# MB9AF15xN register map
File version: 1.7
Registers are 32-bit, read-write, reset 0x0 unless marked. A register's access mark holds for its fields unless they carry their own. Offsets are from the block's base; [hi:lo] are bit positions; {n}, {i} and the like mark numbered series; 'fields as' and 'values as' point back to an identical list.

## WC — Watch Counter
Base 0x4003A000
0x00 WCRD 8-bit ro — Watch Counter Read Register
  [5:0] CTR — counter value
0x01 WCRL 8-bit — Watch Counter Reload Register
  [5:0] RLC — reload value
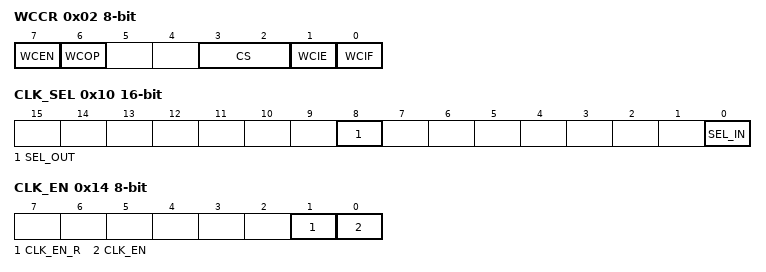
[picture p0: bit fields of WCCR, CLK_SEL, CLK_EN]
0x02 WCCR 8-bit — Watch Counter Control Register
  [7] WCEN — Watch counter operation enable bit
  [6] WCOP ro — Watch counter operating state flag
  [3:2] CS — Count clock select bits
  [1] WCIE — Interrupt request enable bit
  [0] WCIF — Interrupt request flag bit
0x10 CLK_SEL 16-bit — Clock Selection Register
  [8] SEL_OUT — Output clock selection bit
  [0] SEL_IN — Input clock selection bit
0x14 CLK_EN 8-bit — Division Clock Enable Register
  [1] CLK_EN_R — Division clock enable read bit
  [0] CLK_EN — Division clock enable bit

## MFT_PPG — PPG Configuration
Base 0x40024000
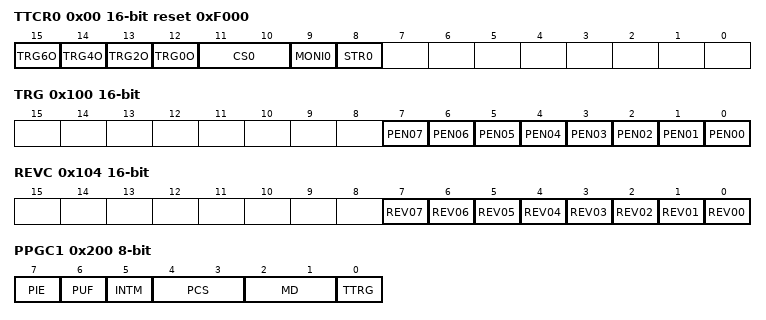
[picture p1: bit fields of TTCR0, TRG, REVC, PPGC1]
0x00 TTCR0 16-bit reset 0xF000 — PPG Start Trigger Control Register 0
  [15] TRG6O — PPG6 trigger stop bit
  [14] TRG4O — PPG4 trigger stop bit
  [13] TRG2O — PPG2 trigger stop bit
  [12] TRG0O — PPG0 trigger stop bit
  [11:10] CS0 — 8-bit UP counter clock select bits for comparison
  [9] MONI0 ro — 8-bit UP counter operation state monitor bit for comparison
  [8] STR0 — 8-bit UP counter operation enable bit for comparison
0x08 COMP0 16-bit (reset mask 0xFF00) — PPG Compare Register 0
0x0C COMP2 8-bit — PPG Compare Register 2
0x10 COMP4 16-bit (reset mask 0xFF00) — PPG Compare Register 4
0x14 COMP6 8-bit — PPG Compare Register 6
0x100 TRG 16-bit — PPG Start Register 0
  [n] PEN{n:02} (n=0..7) — PPG{n} Start Trigger bit
0x104 REVC 16-bit — Output Reverse Register 0
  [n] REV{n:02} (n=0..7) — PPG{n} Output Reverse Enable bit
0x200 PPGC1 8-bit — PPG Operation Mode Control Register 1
  [7] PIE — PPG Interrupt Enable bit
  [6] PUF — PPG Counter Underflow bit
  [5] INTM — Interrupt Mode Select bit
  [4:3] PCS — PPG DOWN Counter Operation Clock Select bits
  [2:1] MD — PPG Operation Mode Set bits
  [0] TTRG — PPG start trigger select bit
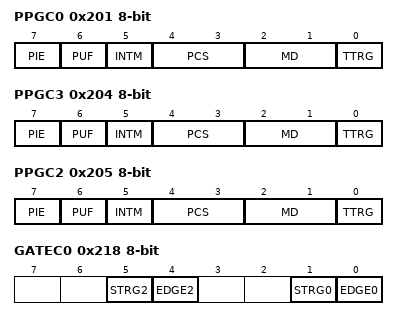
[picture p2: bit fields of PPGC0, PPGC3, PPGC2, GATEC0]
0x201 PPGC0 8-bit — PPG Operation Mode Control Register 0
  fields as PPGC1
0x204 PPGC3 8-bit — PPG Operation Mode Control Register 3
  fields as PPGC1
0x205 PPGC2 8-bit — PPG Operation Mode Control Register 2
  fields as PPGC1
{0x208+4i} PRLL{i} 8-bit reset not defined (i=0..3) — PPG{i} Reload Registers Low
  [7:0] PRLL — Reload Registers Low
{0x209+4i} PRLH{i} 8-bit reset not defined (i=0..3) — PPG{i} Reload Registers High
  [7:0] PRLH — Reload Registers High
0x218 GATEC0 8-bit — PPG Gate Function Control Registers 0
  [5] STRG2 — Select a trigger for PPG2
  [4] EDGE2 — Select Start Effective Level for PPG2
  [1] STRG0 — Select a trigger for PPG0
  [0] EDGE0 — Select Start Effective Level for PPG0
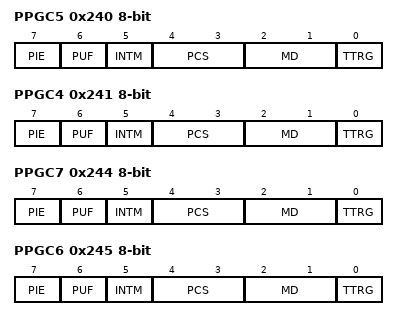
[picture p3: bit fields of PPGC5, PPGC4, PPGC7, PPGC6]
0x240 PPGC5 8-bit — PPG Operation Mode Control Register 5
  fields as PPGC1
0x241 PPGC4 8-bit — PPG Operation Mode Control Register 4
  fields as PPGC1
0x244 PPGC7 8-bit — PPG Operation Mode Control Register 7
  fields as PPGC1
0x245 PPGC6 8-bit — PPG Operation Mode Control Register 6
  fields as PPGC1
{0x238+4i} PRLL{i} 8-bit reset not defined (i=4..7) — PPG{i} Reload Registers Low
  [7:0] PRLL — Reload Registers Low
{0x239+4i} PRLH{i} 8-bit reset not defined (i=4..7) — PPG{i} Reload Registers High
  [7:0] PRLH — Reload Registers High
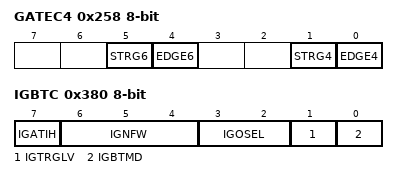
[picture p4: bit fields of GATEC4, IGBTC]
0x258 GATEC4 8-bit — PPG Gate Function Control Registers 4
  [5] STRG6 — Select a trigger for PPG6
  [4] EDGE6 — Select Start Effective Level for PPG6
  [1] STRG4 — Select a trigger for PPG4
  [0] EDGE4 — Select Start Effective Level for PPG4
0x380 IGBTC 8-bit — IGBT Mode Control Register
  [7] IGATIH — Stop prohibition mode selection in output active bit
  [6:4] IGNFW — Noise filter width selection bit
  [3:2] IGOSEL — Output level selection bit
  [1] IGTRGLV — Trigger input level selection bit
  [0] IGBTMD — IGBT mode selection bit
